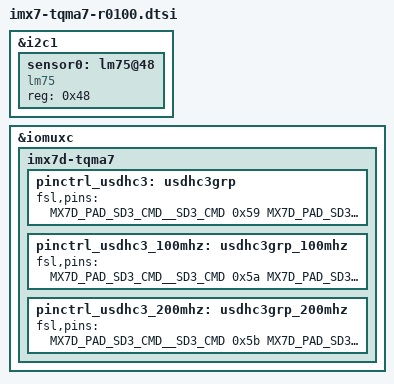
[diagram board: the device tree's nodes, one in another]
/*
 * Copyright (C) 2016-2017 TQ Systems GmbH
 * Author: Markus Niebel <Markus.Niebel@tq-group.com>
 *
 * This file is dual-licensed: you can use it either under the terms
 * of the GPL or the X11 license, at your option. Note that this dual
 * licensing only applies to this file, and not this project as a
 * whole.
 *
 *  a) This file is free software; you can redistribute it and/or
 *     modify it under the terms of the GNU General Public License as
 *     published by the Free Software Foundation; either version 2 of the
 *     License, or (at your option) any later version.
 *
 *     This file is distributed in the hope that it will be useful,
 *     but WITHOUT ANY WARRANTY; without even the implied warranty of
 *     MERCHANTABILITY or FITNESS FOR A PARTICULAR PURPOSE.  See the
 *     GNU General Public License for more details.
 *
 * Or, alternatively,
 *
 *  b) Permission is hereby granted, free of charge, to any person
 *     obtaining a copy of this software and associated documentation
 *     files (the "Software"), to deal in the Software without
 *     restriction, including without limitation the rights to use,
 *     copy, modify, merge, publish, distribute, sublicense, and/or
 *     sell copies of the Software, and to permit persons to whom the
 *     Software is furnished to do so, subject to the following
 *     conditions:
 *
 *     The above copyright notice and this permission notice shall be
 *     included in all copies or substantial portions of the Software.
 *
 *     THE SOFTWARE IS PROVIDED "AS IS", WITHOUT WARRANTY OF ANY KIND,
 *     EXPRESS OR IMPLIED, INCLUDING BUT NOT LIMITED TO THE WARRANTIES
 *     OF MERCHANTABILITY, FITNESS FOR A PARTICULAR PURPOSE AND
 *     NONINFRINGEMENT. IN NO EVENT SHALL THE AUTHORS OR COPYRIGHT
 *     HOLDERS BE LIABLE FOR ANY CLAIM, DAMAGES OR OTHER LIABILITY,
 *     WHETHER IN AN ACTION OF CONTRACT, TORT OR OTHERWISE, ARISING
 *     FROM, OUT OF OR IN CONNECTION WITH THE SOFTWARE OR THE USE OR
 *     OTHER DEALINGS IN THE SOFTWARE.
 */

#include "imx7-tqma7.dtsi"

/delete-node/ &sensor0;
/delete-node/ &eeprom1;

&i2c1 {
	sensor0: lm75@48 {
		compatible = "lm75";
		reg = <0x48>;
	};
};

&iomuxc {
	imx7d-tqma7 {
		pinctrl_usdhc3: usdhc3grp {
			fsl,pins = <
				MX7D_PAD_SD3_CMD__SD3_CMD		0x59
				MX7D_PAD_SD3_CLK__SD3_CLK		0x53
				MX7D_PAD_SD3_DATA0__SD3_DATA0		0x59
				MX7D_PAD_SD3_DATA1__SD3_DATA1		0x59
				MX7D_PAD_SD3_DATA2__SD3_DATA2		0x59
				MX7D_PAD_SD3_DATA3__SD3_DATA3		0x59
				MX7D_PAD_SD3_DATA4__SD3_DATA4		0x59
				MX7D_PAD_SD3_DATA5__SD3_DATA5		0x59
				MX7D_PAD_SD3_DATA6__SD3_DATA6		0x59
				MX7D_PAD_SD3_DATA7__SD3_DATA7		0x59
				MX7D_PAD_SD3_STROBE__SD3_STROBE		0x19
			>;
		};

		pinctrl_usdhc3_100mhz: usdhc3grp_100mhz {
			fsl,pins = <
				MX7D_PAD_SD3_CMD__SD3_CMD		0x5a
				MX7D_PAD_SD3_CLK__SD3_CLK		0x53
				MX7D_PAD_SD3_DATA0__SD3_DATA0		0x5a
				MX7D_PAD_SD3_DATA1__SD3_DATA1		0x5a
				MX7D_PAD_SD3_DATA2__SD3_DATA2		0x5a
				MX7D_PAD_SD3_DATA3__SD3_DATA3		0x5a
				MX7D_PAD_SD3_DATA4__SD3_DATA4		0x5a
				MX7D_PAD_SD3_DATA5__SD3_DATA5		0x5a
				MX7D_PAD_SD3_DATA6__SD3_DATA6		0x5a
				MX7D_PAD_SD3_DATA7__SD3_DATA7		0x5a
				MX7D_PAD_SD3_STROBE__SD3_STROBE		0x1a
			>;
		};

		pinctrl_usdhc3_200mhz: usdhc3grp_200mhz {
			fsl,pins = <
				MX7D_PAD_SD3_CMD__SD3_CMD		0x5b
				MX7D_PAD_SD3_CLK__SD3_CLK		0x53
				MX7D_PAD_SD3_DATA0__SD3_DATA0		0x5b
				MX7D_PAD_SD3_DATA1__SD3_DATA1		0x5b
				MX7D_PAD_SD3_DATA2__SD3_DATA2		0x5b
				MX7D_PAD_SD3_DATA3__SD3_DATA3		0x5b
				MX7D_PAD_SD3_DATA4__SD3_DATA4		0x5b
				MX7D_PAD_SD3_DATA5__SD3_DATA5		0x5b
				MX7D_PAD_SD3_DATA6__SD3_DATA6		0x5b
				MX7D_PAD_SD3_DATA7__SD3_DATA7		0x5b
				MX7D_PAD_SD3_STROBE__SD3_STROBE		0x1b
			>;
		};
	};
};
